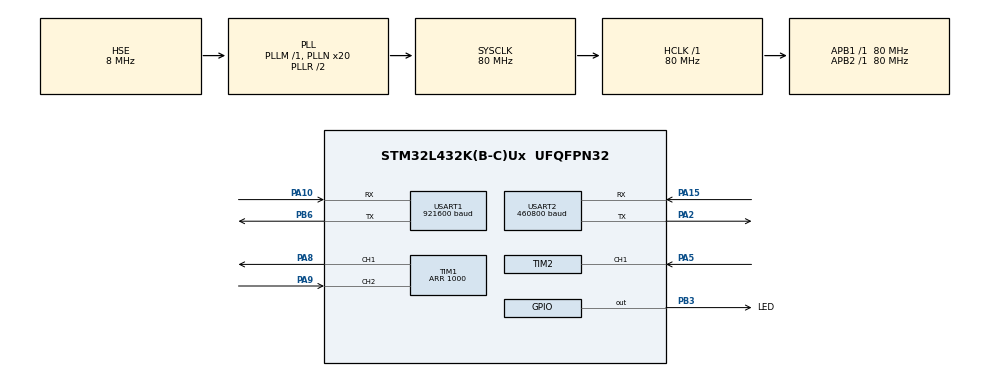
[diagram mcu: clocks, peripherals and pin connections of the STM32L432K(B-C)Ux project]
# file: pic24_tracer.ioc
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Dma.Request0=USART1_RX
Dma.Request1=USART2_TX
Dma.Request2=TIM2_CH1
Dma.Request3=USART2_RX
Dma.TIM2_CH1.2.Direction=DMA_PERIPH_TO_MEMORY
Dma.TIM2_CH1.2.Instance=DMA1_Channel5
Dma.TIM2_CH1.2.MemDataAlignment=DMA_MDATAALIGN_WORD
Dma.TIM2_CH1.2.MemInc=DMA_MINC_ENABLE
Dma.TIM2_CH1.2.Mode=DMA_CIRCULAR
Dma.TIM2_CH1.2.PeriphDataAlignment=DMA_PDATAALIGN_WORD
Dma.TIM2_CH1.2.PeriphInc=DMA_PINC_DISABLE
Dma.TIM2_CH1.2.Priority=DMA_PRIORITY_MEDIUM
Dma.USART1_RX.0.Direction=DMA_PERIPH_TO_MEMORY
Dma.USART1_RX.0.Instance=DMA2_Channel7
Dma.USART1_RX.0.MemDataAlignment=DMA_MDATAALIGN_BYTE
Dma.USART1_RX.0.MemInc=DMA_MINC_ENABLE
Dma.USART1_RX.0.Mode=DMA_CIRCULAR
Dma.USART1_RX.0.PeriphDataAlignment=DMA_PDATAALIGN_BYTE
Dma.USART1_RX.0.PeriphInc=DMA_PINC_DISABLE
Dma.USART1_RX.0.Priority=DMA_PRIORITY_HIGH
Dma.USART2_RX.3.Direction=DMA_PERIPH_TO_MEMORY
Dma.USART2_RX.3.Instance=DMA1_Channel6
Dma.USART2_RX.3.MemDataAlignment=DMA_MDATAALIGN_BYTE
Dma.USART2_RX.3.MemInc=DMA_MINC_ENABLE
Dma.USART2_RX.3.Mode=DMA_CIRCULAR
Dma.USART2_RX.3.PeriphDataAlignment=DMA_PDATAALIGN_BYTE
Dma.USART2_RX.3.PeriphInc=DMA_PINC_DISABLE
Dma.USART2_RX.3.Priority=DMA_PRIORITY_LOW
Dma.USART2_TX.1.Direction=DMA_MEMORY_TO_PERIPH
Dma.USART2_TX.1.Instance=DMA1_Channel7
Dma.USART2_TX.1.MemDataAlignment=DMA_MDATAALIGN_BYTE
Dma.USART2_TX.1.MemInc=DMA_MINC_ENABLE
Dma.USART2_TX.1.Mode=DMA_NORMAL
Dma.USART2_TX.1.PeriphDataAlignment=DMA_PDATAALIGN_BYTE
Dma.USART2_TX.1.PeriphInc=DMA_PINC_DISABLE
Dma.USART2_TX.1.Priority=DMA_PRIORITY_LOW
Mcu.Family=STM32L4
Mcu.Name=STM32L432K(B-C)Ux
Mcu.Package=UFQFPN32
NVIC.DMA1_Channel5_IRQn=true\:0\:0\:false\:false\:true\:false
NVIC.DMA1_Channel6_IRQn=true\:0\:0\:false\:false\:true\:false
NVIC.DMA1_Channel7_IRQn=true\:0\:0\:false\:false\:true\:false
NVIC.DMA2_Channel7_IRQn=true\:0\:0\:false\:false\:true\:false
NVIC.PriorityGroup=NVIC_PRIORITYGROUP_4
NVIC.TIM2_IRQn=true\:0\:0\:false\:false\:true\:true
NVIC.USART2_IRQn=true\:0\:0\:false\:false\:true\:true
PA0.Mode=HSE-External-Clock-Source-for-LittleOrca
PA0.Signal=RCC_CK_IN
PA10.Mode=Asynchronous
PA10.Signal=USART1_RX
PA13\ (JTMS-SWDIO).Mode=Serial_Wire
PA13\ (JTMS-SWDIO).Signal=SYS_JTMS-SWDIO
PA14\ (JTCK-SWCLK).Mode=Serial_Wire
PA14\ (JTCK-SWCLK).Signal=SYS_JTCK-SWCLK
PA15\ (JTDI).Mode=Asynchronous
PA15\ (JTDI).Signal=USART2_RX
PA2.Mode=Asynchronous
PA2.Signal=USART2_TX
PA5.Signal=S_TIM2_CH1
PA8.GPIO_Speed=GPIO_SPEED_FREQ_HIGH
PA8.Signal=S_TIM1_CH1
PA9.Signal=S_TIM1_CH2
PB3\ (JTDO-TRACESWO).GPIO_Label=LED
PB3\ (JTDO-TRACESWO).Signal=GPIO_Output
PB6.Mode=Asynchronous
PB6.Signal=USART1_TX
ProjectManager.HeapSize=0x200
ProjectManager.StackSize=0x400
ProjectManager.TargetToolchain=TrueSTUDIO
RCC.ADCFreq_Value=32000000
RCC.AHBFreq_Value=80000000
RCC.APB1Freq_Value=80000000
RCC.APB1TimFreq_Value=80000000
RCC.APB2Freq_Value=80000000
RCC.APB2TimFreq_Value=80000000
RCC.CortexFreq_Value=80000000
RCC.HCLKFreq_Value=80000000
RCC.HSE_VALUE=8000000
RCC.HSI48_VALUE=48000000
RCC.HSI_VALUE=16000000
RCC.LSE_VALUE=32768
RCC.MSI_VALUE=4000000
RCC.PLLN=20
RCC.PLLSourceVirtual=RCC_PLLSOURCE_HSE
RCC.SYSCLKFreq_VALUE=80000000
RCC.SYSCLKSource=RCC_SYSCLKSOURCE_PLLCLK
RCC.USBFreq_Value=32000000
RCC.VCOOutputFreq_Value=160000000
SH.S_TIM1_CH1.0=TIM1_CH1,Output Compare1 CH1
SH.S_TIM1_CH2.0=TIM1_CH2,TriggerSource_TI2FP2
SH.S_TIM2_CH1.0=TIM2_CH1,Input_Capture1_from_TI1
TIM1.AutoReloadPreload=TIM_AUTORELOAD_PRELOAD_ENABLE
TIM1.Channel-Output\ Compare1\ CH1=TIM_CHANNEL_1
TIM1.OCMode_1=TIM_OCMODE_TOGGLE
TIM1.Period=1000
TIM1.Pulse-Output\ Compare1\ CH1=1
TIM1.Slave_TriggerPolarity=TIM_TRIGGERPOLARITY_FALLING
TIM2.AutoReloadPreload=TIM_AUTORELOAD_PRELOAD_ENABLE
TIM2.Channel-Input_Capture1_from_TI1=TIM_CHANNEL_1
TIM2.ClockDivision=TIM_CLOCKDIVISION_DIV1
TIM2.ICPolarity_CH1=TIM_INPUTCHANNELPOLARITY_BOTHEDGE
TIM2.Period=4294967295
TIM2.Prescaler=1
USART1.BaudRate=921600
USART1.OverSampling=UART_OVERSAMPLING_16
USART1.VirtualMode-Asynchronous=VM_ASYNC
USART1.WordLength=WORDLENGTH_8B
USART2.BaudRate=460800
USART2.VirtualMode-Asynchronous=VM_ASYNC
USART2.WordLength=WORDLENGTH_8B
VP_CRC_VS_CRC.Mode=CRC_Activate
VP_TIM1_VS_ClockSourceINT.Mode=Internal
VP_TIM1_VS_ControllerModeTrigger.Mode=Trigger Mode
VP_TIM1_VS_OPM.Mode=OPM_bit
VP_TIM2_VS_ClockSourceINT.Mode=Internal
board=pic24_tracer

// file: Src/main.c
/**
  ******************************************************************************
  * File Name          : main.c
  * Description        : Main program body
  ******************************************************************************
  ** This notice applies to any and all portions of this file
  * that are not between comment pairs USER CODE BEGIN and
  * USER CODE END. Other portions of this file, whether
  * inserted by the user or by software development tools
  * are owned by their respective copyright owners.
  *
  * COPYRIGHT(c) 2018 STMicroelectronics
  *
  * Redistribution and use in source and binary forms, with or without modification,
  * are permitted provided that the following conditions are met:
  *   1. Redistributions of source code must retain the above copyright notice,
  *      this list of conditions and the following disclaimer.
  *   2. Redistributions in binary form must reproduce the above copyright notice,
  *      this list of conditions and the following disclaimer in the documentation
  *      and/or other materials provided with the distribution.
  *   3. Neither the name of STMicroelectronics nor the names of its contributors
  *      may be used to endorse or promote products derived from this software
  *      without specific prior written permission.
  *
  * THIS SOFTWARE IS PROVIDED BY THE COPYRIGHT HOLDERS AND CONTRIBUTORS "AS IS"
  * AND ANY EXPRESS OR IMPLIED WARRANTIES, INCLUDING, BUT NOT LIMITED TO, THE
  * IMPLIED WARRANTIES OF MERCHANTABILITY AND FITNESS FOR A PARTICULAR PURPOSE ARE
  * DISCLAIMED. IN NO EVENT SHALL THE COPYRIGHT HOLDER OR CONTRIBUTORS BE LIABLE
  * FOR ANY DIRECT, INDIRECT, INCIDENTAL, SPECIAL, EXEMPLARY, OR CONSEQUENTIAL
  * DAMAGES (INCLUDING, BUT NOT LIMITED TO, PROCUREMENT OF SUBSTITUTE GOODS OR
  * SERVICES; LOSS OF USE, DATA, OR PROFITS; OR BUSINESS INTERRUPTION) HOWEVER
  * CAUSED AND ON ANY THEORY OF LIABILITY, WHETHER IN CONTRACT, STRICT LIABILITY,
  * OR TORT (INCLUDING NEGLIGENCE OR OTHERWISE) ARISING IN ANY WAY OUT OF THE USE
  * OF THIS SOFTWARE, EVEN IF ADVISED OF THE POSSIBILITY OF SUCH DAMAGE.
  *
  ******************************************************************************
  */

#include "main.h"
#include "stm32l4xx_hal.h"

/* USER CODE BEGIN Includes */
#include "tracer.h"
/* USER CODE END Includes */

CRC_HandleTypeDef hcrc;

TIM_HandleTypeDef htim1;
TIM_HandleTypeDef htim2;
DMA_HandleTypeDef hdma_tim2_ch1;

UART_HandleTypeDef huart1;
UART_HandleTypeDef huart2;
DMA_HandleTypeDef hdma_usart1_rx;
DMA_HandleTypeDef hdma_usart2_tx;
DMA_HandleTypeDef hdma_usart2_rx;

/* USER CODE BEGIN PV */
/* Private variables ---------------------------------------------------------*/

/* USER CODE END PV */

void SystemClock_Config(void);
static void MX_GPIO_Init(void);
static void MX_DMA_Init(void);
static void MX_USART1_UART_Init(void);
static void MX_USART2_UART_Init(void);
static void MX_TIM2_Init(void);
static void MX_TIM1_Init(void);
static void MX_CRC_Init(void);

void HAL_TIM_MspPostInit(TIM_HandleTypeDef *htim);

/* USER CODE BEGIN PFP */
/* Private function prototypes -----------------------------------------------*/

/* USER CODE END PFP */

int main(void)
{

  /* MCU Configuration----------------------------------------------------------*/

  /* Reset of all peripherals, Initializes the Flash interface and the Systick. */
  HAL_Init();

  /* Configure the system clock */
  SystemClock_Config();

  /* Initialize all configured peripherals */
  MX_GPIO_Init();
  MX_DMA_Init();
  MX_USART1_UART_Init();
  MX_USART2_UART_Init();
  MX_TIM2_Init();
  MX_TIM1_Init();
  MX_CRC_Init();

  /* USER CODE BEGIN 2 */

  /*
   * Concept of operations
   *
   * PIC is sending 'trace' information (2 bytes)
   *
   * The PIC is connected to U1. D1=TX, D0=RX
   * D0 is also connected to the input of TIM1, which is set up in one-pulse mode
   * where a falling edge (start bit) causes the timer to start counting. It counts
   * for approximately the duration of 2 bytes before overflowing and sending an output
   * pulse. This output pulse is read by TIM2, which is simply an up-counting timer. TIM2
   * uses DMA to capture the current time when the TIM1 pulse occurred, effectively
   * timestamping the arrival of the incoming byte of information without causing
   * additional timestamps from the 1's and 0's of the information in the packet. TIM2
   * generates an interrupt on an overflow event (i.e when it resets from 2^32 to 0). This
   * should be sent to the control computer, which can combine these pulses with the
   * timestamps sent in the trace packets into a larger 64-bit timestamp to eliminate
   * roll-over issues.
   *
   * Meanwhile, U1 has also used DMA to save the incoming packet to memory. The U1 DMA
   * is configured in circular mode, and when it is half full an interrupt it triggered.
   * This interrupt notifies the main task that it should generate a packet containing
   * trace packets and associated timestamps to send out U2 via DMA to the control computer.
   *
   * Sending out the trace is minimal overhead on the PIC side, but may be turned
   * off for deployment.
   *
   * Ideally on the STM side, the control computer could send control signals such that
   * the computer can select the timing resolution and start/stop data dumping.
   *
   * NOTE! The timer inputs/outputs have to be physically connected external to the
   * microcontroller.
   *
   */

  tracer(&htim1, &htim2, &huart1, &huart2, &hcrc);

  /* USER CODE END 2 */

  /* Infinite loop */
  while (1)
  {

  }

}

/** System Clock Configuration
*/
void SystemClock_Config(void)
{

  RCC_OscInitTypeDef RCC_OscInitStruct;
  RCC_ClkInitTypeDef RCC_ClkInitStruct;
  RCC_PeriphCLKInitTypeDef PeriphClkInit;

    /**Initializes the CPU, AHB and APB busses clocks
    */
  RCC_OscInitStruct.OscillatorType = RCC_OSCILLATORTYPE_HSE;
  RCC_OscInitStruct.HSEState = RCC_HSE_BYPASS;
  RCC_OscInitStruct.PLL.PLLState = RCC_PLL_ON;
  RCC_OscInitStruct.PLL.PLLSource = RCC_PLLSOURCE_HSE;
  RCC_OscInitStruct.PLL.PLLM = 1;
  RCC_OscInitStruct.PLL.PLLN = 20;
  RCC_OscInitStruct.PLL.PLLP = RCC_PLLP_DIV7;
  RCC_OscInitStruct.PLL.PLLQ = RCC_PLLQ_DIV2;
  RCC_OscInitStruct.PLL.PLLR = RCC_PLLR_DIV2;
  if (HAL_RCC_OscConfig(&RCC_OscInitStruct) != HAL_OK)
  {
    _Error_Handler(__FILE__, __LINE__);
  }

    /**Initializes the CPU, AHB and APB busses clocks
    */
  RCC_ClkInitStruct.ClockType = RCC_CLOCKTYPE_HCLK|RCC_CLOCKTYPE_SYSCLK
                              |RCC_CLOCKTYPE_PCLK1|RCC_CLOCKTYPE_PCLK2;
  RCC_ClkInitStruct.SYSCLKSource = RCC_SYSCLKSOURCE_PLLCLK;
  RCC_ClkInitStruct.AHBCLKDivider = RCC_SYSCLK_DIV1;
  RCC_ClkInitStruct.APB1CLKDivider = RCC_HCLK_DIV1;
  RCC_ClkInitStruct.APB2CLKDivider = RCC_HCLK_DIV1;

  if (HAL_RCC_ClockConfig(&RCC_ClkInitStruct, FLASH_LATENCY_4) != HAL_OK)
  {
    _Error_Handler(__FILE__, __LINE__);
  }

  PeriphClkInit.PeriphClockSelection = RCC_PERIPHCLK_USART1|RCC_PERIPHCLK_USART2;
  PeriphClkInit.Usart1ClockSelection = RCC_USART1CLKSOURCE_PCLK2;
  PeriphClkInit.Usart2ClockSelection = RCC_USART2CLKSOURCE_PCLK1;
  if (HAL_RCCEx_PeriphCLKConfig(&PeriphClkInit) != HAL_OK)
  {
    _Error_Handler(__FILE__, __LINE__);
  }

    /**Configure the main internal regulator output voltage
    */
  if (HAL_PWREx_ControlVoltageScaling(PWR_REGULATOR_VOLTAGE_SCALE1) != HAL_OK)
  {
    _Error_Handler(__FILE__, __LINE__);
  }

    /**Configure the Systick interrupt time
    */
  HAL_SYSTICK_Config(HAL_RCC_GetHCLKFreq()/1000);

    /**Configure the Systick
    */
  HAL_SYSTICK_CLKSourceConfig(SYSTICK_CLKSOURCE_HCLK);

  /* SysTick_IRQn interrupt configuration */
  HAL_NVIC_SetPriority(SysTick_IRQn, 0, 0);
}

/* CRC init function */
static void MX_CRC_Init(void)
{

  hcrc.Instance = CRC;
  hcrc.Init.DefaultPolynomialUse = DEFAULT_POLYNOMIAL_ENABLE;
  hcrc.Init.DefaultInitValueUse = DEFAULT_INIT_VALUE_ENABLE;
  hcrc.Init.InputDataInversionMode = CRC_INPUTDATA_INVERSION_NONE;
  hcrc.Init.OutputDataInversionMode = CRC_OUTPUTDATA_INVERSION_DISABLE;
  hcrc.InputDataFormat = CRC_INPUTDATA_FORMAT_BYTES;
  if (HAL_CRC_Init(&hcrc) != HAL_OK)
  {
    _Error_Handler(__FILE__, __LINE__);
  }

}

/* TIM1 init function */
static void MX_TIM1_Init(void)
{

  TIM_ClockConfigTypeDef sClockSourceConfig;
  TIM_SlaveConfigTypeDef sSlaveConfig;
  TIM_MasterConfigTypeDef sMasterConfig;
  TIM_OC_InitTypeDef sConfigOC;
  TIM_BreakDeadTimeConfigTypeDef sBreakDeadTimeConfig;

  htim1.Instance = TIM1;
  htim1.Init.Prescaler = 0;
  htim1.Init.CounterMode = TIM_COUNTERMODE_UP;
  htim1.Init.Period = 1000;
  htim1.Init.ClockDivision = TIM_CLOCKDIVISION_DIV1;
  htim1.Init.RepetitionCounter = 0;
  htim1.Init.AutoReloadPreload = TIM_AUTORELOAD_PRELOAD_ENABLE;
  if (HAL_TIM_Base_Init(&htim1) != HAL_OK)
  {
    _Error_Handler(__FILE__, __LINE__);
  }

  sClockSourceConfig.ClockSource = TIM_CLOCKSOURCE_INTERNAL;
  if (HAL_TIM_ConfigClockSource(&htim1, &sClockSourceConfig) != HAL_OK)
  {
    _Error_Handler(__FILE__, __LINE__);
  }

  if (HAL_TIM_OC_Init(&htim1) != HAL_OK)
  {
    _Error_Handler(__FILE__, __LINE__);
  }

  if (HAL_TIM_OnePulse_Init(&htim1, TIM_OPMODE_SINGLE) != HAL_OK)
  {
    _Error_Handler(__FILE__, __LINE__);
  }

  sSlaveConfig.SlaveMode = TIM_SLAVEMODE_TRIGGER;
  sSlaveConfig.InputTrigger = TIM_TS_TI2FP2;
  sSlaveConfig.TriggerPolarity = TIM_TRIGGERPOLARITY_FALLING;
  sSlaveConfig.TriggerFilter = 0;
  if (HAL_TIM_SlaveConfigSynchronization(&htim1, &sSlaveConfig) != HAL_OK)
  {
    _Error_Handler(__FILE__, __LINE__);
  }

  sMasterConfig.MasterOutputTrigger = TIM_TRGO_RESET;
  sMasterConfig.MasterOutputTrigger2 = TIM_TRGO2_RESET;
  sMasterConfig.MasterSlaveMode = TIM_MASTERSLAVEMODE_DISABLE;
  if (HAL_TIMEx_MasterConfigSynchronization(&htim1, &sMasterConfig) != HAL_OK)
  {
    _Error_Handler(__FILE__, __LINE__);
  }

  sConfigOC.OCMode = TIM_OCMODE_TOGGLE;
  sConfigOC.Pulse = 1;
  sConfigOC.OCPolarity = TIM_OCPOLARITY_HIGH;
  sConfigOC.OCNPolarity = TIM_OCNPOLARITY_HIGH;
  sConfigOC.OCFastMode = TIM_OCFAST_DISABLE;
  sConfigOC.OCIdleState = TIM_OCIDLESTATE_RESET;
  sConfigOC.OCNIdleState = TIM_OCNIDLESTATE_RESET;
  if (HAL_TIM_OC_ConfigChannel(&htim1, &sConfigOC, TIM_CHANNEL_1) != HAL_OK)
  {
    _Error_Handler(__FILE__, __LINE__);
  }

  sBreakDeadTimeConfig.OffStateRunMode = TIM_OSSR_DISABLE;
  sBreakDeadTimeConfig.OffStateIDLEMode = TIM_OSSI_DISABLE;
  sBreakDeadTimeConfig.LockLevel = TIM_LOCKLEVEL_OFF;
  sBreakDeadTimeConfig.DeadTime = 0;
  sBreakDeadTimeConfig.BreakState = TIM_BREAK_DISABLE;
  sBreakDeadTimeConfig.BreakPolarity = TIM_BREAKPOLARITY_HIGH;
  sBreakDeadTimeConfig.BreakFilter = 0;
  sBreakDeadTimeConfig.Break2State = TIM_BREAK2_DISABLE;
  sBreakDeadTimeConfig.Break2Polarity = TIM_BREAK2POLARITY_HIGH;
  sBreakDeadTimeConfig.Break2Filter = 0;
  sBreakDeadTimeConfig.AutomaticOutput = TIM_AUTOMATICOUTPUT_DISABLE;
  if (HAL_TIMEx_ConfigBreakDeadTime(&htim1, &sBreakDeadTimeConfig) != HAL_OK)
  {
    _Error_Handler(__FILE__, __LINE__);
  }

  HAL_TIM_MspPostInit(&htim1);

}

/* TIM2 init function */
static void MX_TIM2_Init(void)
{

  TIM_ClockConfigTypeDef sClockSourceConfig;
  TIM_MasterConfigTypeDef sMasterConfig;
  TIM_IC_InitTypeDef sConfigIC;

  htim2.Instance = TIM2;
  htim2.Init.Prescaler = 1;
  htim2.Init.CounterMode = TIM_COUNTERMODE_UP;
  htim2.Init.Period = 4294967295;
  htim2.Init.ClockDivision = TIM_CLOCKDIVISION_DIV1;
  htim2.Init.AutoReloadPreload = TIM_AUTORELOAD_PRELOAD_ENABLE;
  if (HAL_TIM_Base_Init(&htim2) != HAL_OK)
  {
    _Error_Handler(__FILE__, __LINE__);
  }

  sClockSourceConfig.ClockSource = TIM_CLOCKSOURCE_INTERNAL;
  if (HAL_TIM_ConfigClockSource(&htim2, &sClockSourceConfig) != HAL_OK)
  {
    _Error_Handler(__FILE__, __LINE__);
  }

  if (HAL_TIM_IC_Init(&htim2) != HAL_OK)
  {
    _Error_Handler(__FILE__, __LINE__);
  }

  sMasterConfig.MasterOutputTrigger = TIM_TRGO_RESET;
  sMasterConfig.MasterSlaveMode = TIM_MASTERSLAVEMODE_DISABLE;
  if (HAL_TIMEx_MasterConfigSynchronization(&htim2, &sMasterConfig) != HAL_OK)
  {
    _Error_Handler(__FILE__, __LINE__);
  }

  sConfigIC.ICPolarity = TIM_INPUTCHANNELPOLARITY_BOTHEDGE;
  sConfigIC.ICSelection = TIM_ICSELECTION_DIRECTTI;
  sConfigIC.ICPrescaler = TIM_ICPSC_DIV1;
  sConfigIC.ICFilter = 0;
  if (HAL_TIM_IC_ConfigChannel(&htim2, &sConfigIC, TIM_CHANNEL_1) != HAL_OK)
  {
    _Error_Handler(__FILE__, __LINE__);
  }

}

/* USART1 init function */
static void MX_USART1_UART_Init(void)
{

  huart1.Instance = USART1;
  huart1.Init.BaudRate = 921600;
  huart1.Init.WordLength = UART_WORDLENGTH_8B;
  huart1.Init.StopBits = UART_STOPBITS_1;
  huart1.Init.Parity = UART_PARITY_NONE;
  huart1.Init.Mode = UART_MODE_TX_RX;
  huart1.Init.HwFlowCtl = UART_HWCONTROL_NONE;
  huart1.Init.OverSampling = UART_OVERSAMPLING_16;
  huart1.Init.OneBitSampling = UART_ONE_BIT_SAMPLE_DISABLE;
  huart1.AdvancedInit.AdvFeatureInit = UART_ADVFEATURE_NO_INIT;
  if (HAL_UART_Init(&huart1) != HAL_OK)
  {
    _Error_Handler(__FILE__, __LINE__);
  }

}

/* USART2 init function */
static void MX_USART2_UART_Init(void)
{

  huart2.Instance = USART2;
  huart2.Init.BaudRate = 460800;
  huart2.Init.WordLength = UART_WORDLENGTH_8B;
  huart2.Init.StopBits = UART_STOPBITS_1;
  huart2.Init.Parity = UART_PARITY_NONE;
  huart2.Init.Mode = UART_MODE_TX_RX;
  huart2.Init.HwFlowCtl = UART_HWCONTROL_NONE;
  huart2.Init.OverSampling = UART_OVERSAMPLING_16;
  huart2.Init.OneBitSampling = UART_ONE_BIT_SAMPLE_DISABLE;
  huart2.AdvancedInit.AdvFeatureInit = UART_ADVFEATURE_NO_INIT;
  if (HAL_UART_Init(&huart2) != HAL_OK)
  {
    _Error_Handler(__FILE__, __LINE__);
  }

}

static void MX_DMA_Init(void)
{
  /* DMA controller clock enable */
  __HAL_RCC_DMA2_CLK_ENABLE();
  __HAL_RCC_DMA1_CLK_ENABLE();

  /* DMA interrupt init */
  /* DMA1_Channel5_IRQn interrupt configuration */
  HAL_NVIC_SetPriority(DMA1_Channel5_IRQn, 0, 0);
  HAL_NVIC_EnableIRQ(DMA1_Channel5_IRQn);
  /* DMA1_Channel6_IRQn interrupt configuration */
  HAL_NVIC_SetPriority(DMA1_Channel6_IRQn, 0, 0);
  HAL_NVIC_EnableIRQ(DMA1_Channel6_IRQn);
  /* DMA1_Channel7_IRQn interrupt configuration */
  HAL_NVIC_SetPriority(DMA1_Channel7_IRQn, 0, 0);
  HAL_NVIC_EnableIRQ(DMA1_Channel7_IRQn);
  /* DMA2_Channel7_IRQn interrupt configuration */
  HAL_NVIC_SetPriority(DMA2_Channel7_IRQn, 0, 0);
  HAL_NVIC_EnableIRQ(DMA2_Channel7_IRQn);

}

/** Configure pins as
        * Analog
        * Input
        * Output
        * EVENT_OUT
        * EXTI
*/
static void MX_GPIO_Init(void)
{

  GPIO_InitTypeDef GPIO_InitStruct;

  /* GPIO Ports Clock Enable */
  __HAL_RCC_GPIOA_CLK_ENABLE();
  __HAL_RCC_GPIOB_CLK_ENABLE();

  /*Configure GPIO pin Output Level */
  HAL_GPIO_WritePin(LED_GPIO_Port, LED_Pin, GPIO_PIN_RESET);

  /*Configure GPIO pin : LED_Pin */
  GPIO_InitStruct.Pin = LED_Pin;
  GPIO_InitStruct.Mode = GPIO_MODE_OUTPUT_PP;
  GPIO_InitStruct.Pull = GPIO_NOPULL;
  GPIO_InitStruct.Speed = GPIO_SPEED_FREQ_LOW;
  HAL_GPIO_Init(LED_GPIO_Port, &GPIO_InitStruct);

}

void _Error_Handler(char * file, int line)
{
  while(1)
  {
  }
}

/************************ (C) COPYRIGHT STMicroelectronics *****END OF FILE****/
